# I94100_v1_3 register map
File version: 1.0
I94100_v1_3 SVD file
Registers are 32-bit, read-write, reset 0x0 unless marked. A register's access mark holds for its fields unless they carry their own. Offsets are from the block's base; lines under a group give offsets from that group; [hi:lo] are bit positions; {n}, {i} and the like mark numbered series; 'fields as' and 'values as' point back to an identical list; <NAME> marks a mode.

## Memory map
0x00300000 FMC_CONFIG size 0xC — ConfigurationBytes Register Map
0x40000000 SYS blocks up to offset 0x114 — SYS Register Map
0x40000200 CLK blocks up to offset 0xB4 — CLK Register Map
0x40000300 NMI size 0x8 — NMI Register Map
0x40004000 GPIO blocks up to offset 0x900 — GPIO Register Map
0x40008000 PDMA blocks up to offset 0x530 — PDMA Register Map
0x4000C000 FMC blocks up to offset 0xC8 — FMC Register Map
0x40031000 CRC size 0x10 — CRC Register Map
0x40040000 WDT size 0x8 — WDT Register Map
0x40040100 WWDT size 0x10 — WWDT Register Map
0x40041000 RTC blocks up to offset 0x104 — RTC Register Map
0x40043000 EADC blocks up to offset 0x204 — EADC Register Map
0x40048000 I2S blocks up to offset 0x28 — I2S Register Map
0x40050000 TMR01 blocks up to offset 0x1A8 — TIMER Register Map
0x40051000 TMR23 blocks up to offset 0x1A8 — TIMER Register Map
0x40058000 PWM0 blocks up to offset 0x350 — PWM Register Map
0x40060000 SPI0 blocks up to offset 0x34 — SPI Register Map
0x40061000 SPI1 blocks up to offset 0x6C — SPI Register Map
0x40062000 SPI2 blocks up to offset 0x6C — SPI Register Map
0x40063000 DMIC size 0x14 — DMIC Register Map
0x40063100 VAD size 0x28 — VAD Register Map
0x40064000 DPWM blocks up to offset 0x1C8 — DPWM Register Map
0x40070000 UART0 blocks up to offset 0x4C — UART Register Map
0x40080000 I2C0 blocks up to offset 0x6C — I2C Register Map
0x40081000 I2C1 blocks up to offset 0x6C — I2C Register Map
0x400C0000 USBD blocks up to offset 0x5C0 — USBD Register Map
0xE000E000 SCS blocks up to offset 0xD24 — SYST_SCR Register Map

## NMI — NMI Register Map
Base 0x40000300
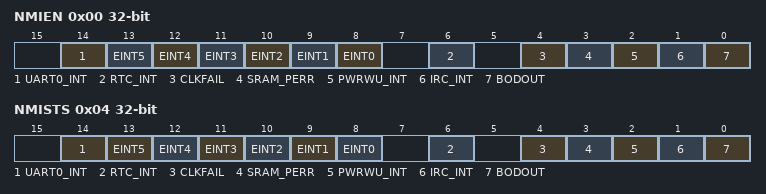
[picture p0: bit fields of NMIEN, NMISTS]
0x00 NMIEN — NMI Source Interrupt Enable Register
  [14] UART0_INT — UART0 NMI Source Enable (Write Protected). Note: This bit is write protected. Refer to the SYS_REGLCTL register.
    0=UART0 NMI source Disabled; 1=UART0 NMI source Enabled
  [13] EINT5 — External Interrupt 5 NMI Source Enable (Write Protect). Note: This bit is write protected. Refer to the SYS_REGLCTL register.
    0=External interrupt 5 NMI source Disabled; 1=External interrupt 5 NMI source Enabled
  [n+8] EINT{n} (n=0..4) — External Interrupt {n} NMI Source Enable (Write Protected). Note: This bit is write protected. Refer to the SYS_REGLCTL register.
    0=External interrupt {n} NMI source Disabled; 1=External interrupt {n} NMI source Enabled
  [6] RTC_INT — RTC NMI Source Enable (Write Protected). Note: This bit is write protected. Refer to the SYS_REGLCTL register.
    0=RTC NMI source Disabled; 1=RTC NMI source Enabled
  [4] CLKFAIL — Clock Fail Detected NMI Source Enable (Write Protected). Note: This bit is write protected. Refer to the SYS_REGLCTL register.
    0=Clock fail detected interrupt NMI source Disabled; 1=Clock fail detected interrupt NMI source Enabled
  [3] SRAM_PERR — SRAM Parity Check Error NMI Source Enable (Write Protected). Note: This bit is write protected. Refer to the SYS_REGLCTL register.
    0=SRAM parity check error NMI source Disabled; 1=SRAM parity check error NMI source Enabled
  [2] PWRWU_INT — Power-down Mode Wake-up NMI Source Enable (Write Protected). Note: This bit is write protected. Refer to the SYS_REGLCTL register.
    0=Power-down mode wake-up NMI source Disabled; 1=Power-down mode wake-up NMI source Enabled
  [1] IRC_INT — IRC TRIM NMI Source Enable (Write Protected). Note: This bit is write protected. Refer to the SYS_REGLCTL register.
    0=IRC TRIM NMI source Disabled; 1=IRC TRIM NMI source Enabled
  [0] BODOUT — BOD NMI Source Enable (Write Protected). Note: This bit is write protected. Refer to the SYS_REGLCTL register.
    0=BOD NMI source Disabled; 1=BOD NMI source Enabled
0x04 NMISTS ro — NMI Source Interrupt Status Register
  [14] UART0_INT — UART0 Interrupt Flag (Read Only)
    0=UART0 interrupt is deasserted; 1=UART0 interrupt is asserted
  [n+8] EINT{n} (n=0..5) — External Interrupt {n} Interrupt Flag (Read Only)
    0=External Interrupt {n} interrupt is deasserted; 1=External Interrupt {n} interrupt is asserted
  [6] RTC_INT — RTC Interrupt Flag (Read Only)
    0=RTC interrupt is deasserted; 1=RTC interrupt is asserted
  [4] CLKFAIL — Clock Fail Detected Interrupt Flag (Read Only)
    0=Clock fail detected interrupt is deasserted; 1=Clock fail detected interrupt is asserted
  [3] SRAM_PERR — SRAM Parity Check Error Interrupt Flag (Read Only)
    0=SRAM parity check error interrupt is deasserted; 1=SRAM parity check error interrupt is asserted
  [2] PWRWU_INT — Power-down Mode Wake-up Interrupt Flag (Read Only)
    0=Power-down mode wake-up interrupt is deasserted; 1=Power-down mode wake-up interrupt is asserted
  [1] IRC_INT — IRC TRIM Interrupt Flag (Read Only)
    0=HIRC TRIM interrupt is deasserted; 1=HIRC TRIM interrupt is asserted
  [0] BODOUT — BOD Interrupt Flag (Read Only)
    0=BOD interrupt is deasserted; 1=BOD interrupt is asserted
